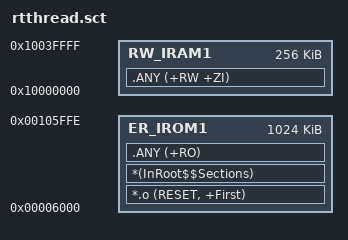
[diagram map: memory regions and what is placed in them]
; *************************************************************
; *** Scatter-Loading Description File generated by uVision ***
; *************************************************************

LR_IROM1 0x00006000 0x000FFFFF  {    ; load region size_region
  ER_IROM1 0x00006000 0x000FFFFF  {  ; load address = execution address
   *.o (RESET, +First)
   *(InRoot$$Sections)
   .ANY (+RO)
  }
  RW_IRAM1 0x10000000 0x00040000  {  ; RW data
   .ANY (+RW +ZI)
  }
}
